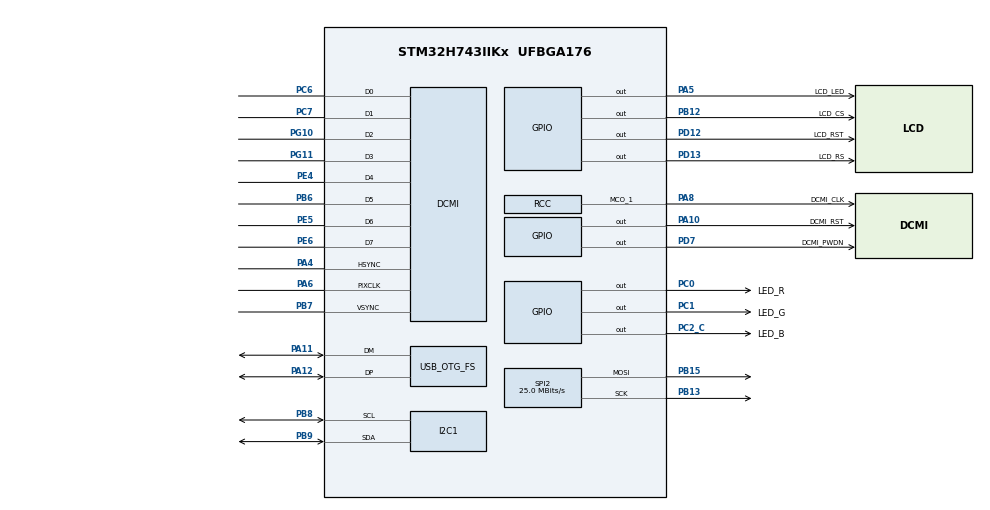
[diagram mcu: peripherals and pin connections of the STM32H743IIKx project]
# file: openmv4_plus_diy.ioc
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CORTEX_M7.CPU_DCache=Disabled
CORTEX_M7.CPU_ICache=Enabled
CORTEX_M7.MPU_Control=__NULL
CORTEX_M7.default_mode_Activation=1
DCMI.HSPolarity=DCMI_HSPOLARITY_LOW
DCMI.JPEGMode=DCMI_JPEG_ENABLE
DCMI.PCKPolarity=DCMI_PCKPOLARITY_RISING
DCMI.VSPolarity=DCMI_VSPOLARITY_LOW
Dma.DCMI.0.Direction=DMA_PERIPH_TO_MEMORY
Dma.DCMI.0.EventEnable=DISABLE
Dma.DCMI.0.FIFOMode=DMA_FIFOMODE_ENABLE
Dma.DCMI.0.FIFOThreshold=DMA_FIFO_THRESHOLD_HALFFULL
Dma.DCMI.0.Instance=DMA1_Stream1
Dma.DCMI.0.MemBurst=DMA_MBURST_SINGLE
Dma.DCMI.0.MemDataAlignment=DMA_MDATAALIGN_WORD
Dma.DCMI.0.MemInc=DMA_MINC_ENABLE
Dma.DCMI.0.Mode=DMA_CIRCULAR
Dma.DCMI.0.PeriphBurst=DMA_PBURST_SINGLE
Dma.DCMI.0.PeriphDataAlignment=DMA_PDATAALIGN_WORD
Dma.DCMI.0.PeriphInc=DMA_PINC_DISABLE
Dma.DCMI.0.Polarity=HAL_DMAMUX_REQ_GEN_RISING
Dma.DCMI.0.Priority=DMA_PRIORITY_HIGH
Dma.DCMI.0.RequestNumber=1
Dma.DCMI.0.SignalID=NONE
Dma.DCMI.0.SyncEnable=DISABLE
Dma.DCMI.0.SyncPolarity=HAL_DMAMUX_SYNC_NO_EVENT
Dma.DCMI.0.SyncRequestNumber=1
Dma.DCMI.0.SyncSignalID=NONE
Dma.Request0=DCMI
Dma.Request1=SPI2_TX
Dma.SPI2_TX.1.Direction=DMA_MEMORY_TO_PERIPH
Dma.SPI2_TX.1.EventEnable=DISABLE
Dma.SPI2_TX.1.FIFOMode=DMA_FIFOMODE_DISABLE
Dma.SPI2_TX.1.Instance=DMA1_Stream5
Dma.SPI2_TX.1.MemDataAlignment=DMA_MDATAALIGN_HALFWORD
Dma.SPI2_TX.1.MemInc=DMA_MINC_ENABLE
Dma.SPI2_TX.1.Mode=DMA_NORMAL
Dma.SPI2_TX.1.PeriphDataAlignment=DMA_PDATAALIGN_HALFWORD
Dma.SPI2_TX.1.PeriphInc=DMA_PINC_DISABLE
Dma.SPI2_TX.1.Polarity=HAL_DMAMUX_REQ_GEN_RISING
Dma.SPI2_TX.1.Priority=DMA_PRIORITY_LOW
Dma.SPI2_TX.1.RequestNumber=1
Dma.SPI2_TX.1.SignalID=NONE
Dma.SPI2_TX.1.SyncEnable=DISABLE
Dma.SPI2_TX.1.SyncPolarity=HAL_DMAMUX_SYNC_NO_EVENT
Dma.SPI2_TX.1.SyncRequestNumber=1
Dma.SPI2_TX.1.SyncSignalID=NONE
I2C1.Timing=0x10C0ECFF
Mcu.Family=STM32H7
Mcu.Name=STM32H743IIKx
Mcu.Package=UFBGA176
NVIC.DCMI_IRQn=true\:0\:0\:false\:false\:true\:true\:true\:true
NVIC.DMA1_Stream1_IRQn=true\:0\:0\:false\:false\:true\:false\:true\:true
NVIC.DMA1_Stream5_IRQn=true\:3\:0\:true\:false\:true\:false\:true\:true
NVIC.OTG_FS_IRQn=true\:0\:0\:false\:false\:true\:false\:true\:true
NVIC.PriorityGroup=NVIC_PRIORITYGROUP_4
NVIC.SPI2_IRQn=true\:2\:0\:true\:false\:true\:false\:true\:true
PA10.GPIO_Label=DCMI_RST
PA10.GPIO_PuPd=GPIO_PULLUP
PA10.PinState=GPIO_PIN_SET
PA10.Signal=GPIO_Output
PA11.Mode=Device_Only
PA11.Signal=USB_OTG_FS_DM
PA12.Mode=Device_Only
PA12.Signal=USB_OTG_FS_DP
PA13\ (JTMS/SWDIO).Mode=Serial_Wire
PA13\ (JTMS/SWDIO).Signal=DEBUG_JTMS-SWDIO
PA14\ (JTCK/SWCLK).Mode=Serial_Wire
PA14\ (JTCK/SWCLK).Signal=DEBUG_JTCK-SWCLK
PA4.GPIO_Speed=GPIO_SPEED_FREQ_VERY_HIGH
PA4.Mode=Slave_8_bits_External_Synchro
PA4.Signal=DCMI_HSYNC
PA5.GPIO_Label=LCD_LED
PA5.Signal=GPIO_Output
PA6.GPIO_PuPd=GPIO_PULLUP
PA6.GPIO_Speed=GPIO_SPEED_FREQ_VERY_HIGH
PA6.Mode=Slave_8_bits_External_Synchro
PA6.Signal=DCMI_PIXCLK
PA8.GPIO_Label=DCMI_CLK
PA8.GPIO_Speed=GPIO_SPEED_FREQ_VERY_HIGH
PA8.Mode=Clock-out-1
PA8.Signal=RCC_MCO_1
PB12.GPIO_Label=LCD_CS
PB12.Signal=GPIO_Output
PB13.Mode=TX_Only_Simplex_Unidirect_Master
PB13.Signal=SPI2_SCK
PB14.Signal=SPI2_MISO
PB15.Mode=TX_Only_Simplex_Unidirect_Master
PB15.Signal=SPI2_MOSI
PB6.GPIO_Speed=GPIO_SPEED_FREQ_VERY_HIGH
PB6.Mode=Slave_8_bits_External_Synchro
PB6.Signal=DCMI_D5
PB7.GPIO_Speed=GPIO_SPEED_FREQ_VERY_HIGH
PB7.Mode=Slave_8_bits_External_Synchro
PB7.Signal=DCMI_VSYNC
PB8.Mode=I2C
PB8.Signal=I2C1_SCL
PB9.Mode=I2C
PB9.Signal=I2C1_SDA
PC0.GPIO_Label=LED_R
PC0.PinState=GPIO_PIN_SET
PC0.Signal=GPIO_Output
PC1.GPIO_Label=LED_G
PC1.PinState=GPIO_PIN_SET
PC1.Signal=GPIO_Output
PC2_C.GPIO_Label=LED_B
PC2_C.PinState=GPIO_PIN_SET
PC2_C.Signal=GPIO_Output
PC6.GPIO_Speed=GPIO_SPEED_FREQ_VERY_HIGH
PC6.Mode=Slave_8_bits_External_Synchro
PC6.Signal=DCMI_D0
PC7.GPIO_Speed=GPIO_SPEED_FREQ_VERY_HIGH
PC7.Mode=Slave_8_bits_External_Synchro
PC7.Signal=DCMI_D1
PD12.GPIO_Label=LCD_RST
PD12.Signal=GPIO_Output
PD13.GPIO_Label=LCD_RS
PD13.Signal=GPIO_Output
PD7.GPIO_Label=DCMI_PWDN
PD7.GPIO_PuPd=GPIO_PULLUP
PD7.PinState=GPIO_PIN_SET
PD7.Signal=GPIO_Output
PE4.GPIO_Speed=GPIO_SPEED_FREQ_VERY_HIGH
PE4.Mode=Slave_8_bits_External_Synchro
PE4.Signal=DCMI_D4
PE5.GPIO_Speed=GPIO_SPEED_FREQ_VERY_HIGH
PE5.Mode=Slave_8_bits_External_Synchro
PE5.Signal=DCMI_D6
PE6.GPIO_Speed=GPIO_SPEED_FREQ_VERY_HIGH
PE6.Mode=Slave_8_bits_External_Synchro
PE6.Signal=DCMI_D7
PG10.GPIO_Speed=GPIO_SPEED_FREQ_VERY_HIGH
PG10.Mode=Slave_8_bits_External_Synchro
PG10.Signal=DCMI_D2
PG11.GPIO_Speed=GPIO_SPEED_FREQ_VERY_HIGH
PG11.Mode=Slave_8_bits_External_Synchro
PG11.Signal=DCMI_D3
PH0-OSC_IN\ (PH0).Mode=HSE-External-Oscillator
PH0-OSC_IN\ (PH0).Signal=RCC_OSC_IN
PH1-OSC_OUT\ (PH1).Mode=HSE-External-Oscillator
PH1-OSC_OUT\ (PH1).Signal=RCC_OSC_OUT
ProjectManager.HeapSize=0x2000
ProjectManager.StackSize=0x4000
ProjectManager.TargetToolchain=STM32CubeIDE
RCC.ADCFreq_Value=24187500
RCC.APB1Freq_Value=100000000
RCC.APB2Freq_Value=100000000
RCC.APB3Freq_Value=100000000
RCC.APB4Freq_Value=100000000
RCC.CortexFreq_Value=400000000
RCC.D1PPRE=RCC_APB3_DIV2
RCC.D2PPRE1=RCC_APB1_DIV2
RCC.D2PPRE2=RCC_APB2_DIV2
RCC.D3PPRE=RCC_APB4_DIV2
RCC.DIVM1=3
RCC.DIVM3=20
RCC.DIVN1=200
RCC.DIVQ1=8
RCC.HCLKFreq_Value=200000000
RCC.HPRE=RCC_HCLK_DIV2
RCC.HSE_VALUE=12000000
RCC.PLL2FRACN=0
RCC.PLL3FRACN=0
RCC.PLLFRACN=0
RCC.PLLSourceVirtual=RCC_PLLSOURCE_HSE
RCC.RCC_MCO1Source=RCC_MCO1SOURCE_HSI48
RCC.SYSCLKFreq_VALUE=400000000
RCC.SYSCLKSource=RCC_SYSCLKSOURCE_PLLCLK
RCC.Tim1Mul=2
RCC.USBCLockSelection=RCC_USBCLKSOURCE_HSI48
RCC.USBFreq_Value=48000000
SPI2.BaudRatePrescaler=SPI_BAUDRATEPRESCALER_4
SPI2.CalculateBaudRate=25.0 MBits/s
SPI2.DataSize=SPI_DATASIZE_8BIT
SPI2.Direction=SPI_DIRECTION_2LINES_TXONLY
SPI2.Mode=SPI_MODE_MASTER
SPI2.VirtualType=VM_MASTER
USB_DEVICE.CLASS_NAME_FS=CDC
USB_DEVICE.VirtualMode-CDC_FS=Cdc
USB_DEVICE.VirtualModeFS=Cdc_FS
USB_OTG_FS.VirtualMode=Device_Only
VP_CRC_VS_CRC.Mode=CRC_Activate
VP_USB_DEVICE_VS_USB_DEVICE_CDC_FS.Mode=CDC_FS
board=custom

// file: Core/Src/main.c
/* USER CODE BEGIN Header */
/**
  ******************************************************************************
  * @file           : main.c
  * @brief          : Main program body
  ******************************************************************************
  * @attention
  *
  * Copyright (c) 2023 STMicroelectronics.
  * All rights reserved.
  *
  * This software is licensed under terms that can be found in the LICENSE file
  * in the root directory of this software component.
  * If no LICENSE file comes with this software, it is provided AS-IS.
  *
  ******************************************************************************
  */
/* USER CODE END Header */
#include "main.h"
#include "crc.h"
#include "dcmi.h"
#include "dma.h"
#include "i2c.h"
#include "spi.h"
#include "usb_device.h"
#include "gpio.h"

/* USER CODE BEGIN Includes */
#include "usb_bsp.h"
#include "camera_run.h"
#include "lcd_display.h"
/* USER CODE END Includes */

void SystemClock_Config(void);

/* USER CODE BEGIN 0 */
uint8_t test_buf[100];
/* USER CODE END 0 */

int main(void)
{

  /* Enable I-Cache---------------------------------------------------------*/
  SCB_EnableICache();

  /* MCU Configuration--------------------------------------------------------*/

  /* Reset of all peripherals, Initializes the Flash interface and the Systick. */
  HAL_Init();

  /* Configure the system clock */
  SystemClock_Config();

  /* Initialize all configured peripherals */
  MX_GPIO_Init();
  MX_DMA_Init();
  MX_USB_DEVICE_Init();
  MX_DCMI_Init();
  MX_I2C1_Init();
  MX_SPI2_Init();
  MX_CRC_Init();

  /* Infinite loop */
  /* USER CODE BEGIN WHILE */
  usb_printf("openmv4 plus board diy\r\n");
  lcd_init();
  camera_RGB565_init();
//  camera_JPEG_init();
  while (1)
  {
    /* USER CODE END WHILE */

    /* USER CODE BEGIN 3 */
//	  usb_send_data(test_buf,100);
//	  usb_printf("openmv4 plus board diy\r\n");
//	  HAL_Delay(1000);
//	  HAL_GPIO_TogglePin(LED_R_GPIO_Port,LED_R_Pin);
//	  HAL_GPIO_TogglePin(LED_G_GPIO_Port,LED_G_Pin);
//	  HAL_GPIO_TogglePin(LED_B_GPIO_Port,LED_B_Pin);
	  TFT_LCD_RGB565_run();
//	  JPEG_run();
  }
  /* USER CODE END 3 */
}

void SystemClock_Config(void)
{
  RCC_OscInitTypeDef RCC_OscInitStruct = {0};
  RCC_ClkInitTypeDef RCC_ClkInitStruct = {0};

  /** Supply configuration update enable
  */
  HAL_PWREx_ConfigSupply(PWR_LDO_SUPPLY);

  /** Configure the main internal regulator output voltage
  */
  __HAL_PWR_VOLTAGESCALING_CONFIG(PWR_REGULATOR_VOLTAGE_SCALE1);

  while(!__HAL_PWR_GET_FLAG(PWR_FLAG_VOSRDY)) {}

  /** Initializes the RCC Oscillators according to the specified parameters
  * in the RCC_OscInitTypeDef structure.
  */
  RCC_OscInitStruct.OscillatorType = RCC_OSCILLATORTYPE_HSI48|RCC_OSCILLATORTYPE_HSE;
  RCC_OscInitStruct.HSEState = RCC_HSE_ON;
  RCC_OscInitStruct.HSI48State = RCC_HSI48_ON;
  RCC_OscInitStruct.PLL.PLLState = RCC_PLL_ON;
  RCC_OscInitStruct.PLL.PLLSource = RCC_PLLSOURCE_HSE;
  RCC_OscInitStruct.PLL.PLLM = 3;
  RCC_OscInitStruct.PLL.PLLN = 200;
  RCC_OscInitStruct.PLL.PLLP = 2;
  RCC_OscInitStruct.PLL.PLLQ = 8;
  RCC_OscInitStruct.PLL.PLLR = 2;
  RCC_OscInitStruct.PLL.PLLRGE = RCC_PLL1VCIRANGE_2;
  RCC_OscInitStruct.PLL.PLLVCOSEL = RCC_PLL1VCOWIDE;
  RCC_OscInitStruct.PLL.PLLFRACN = 0;
  if (HAL_RCC_OscConfig(&RCC_OscInitStruct) != HAL_OK)
  {
    Error_Handler();
  }

  /** Initializes the CPU, AHB and APB buses clocks
  */
  RCC_ClkInitStruct.ClockType = RCC_CLOCKTYPE_HCLK|RCC_CLOCKTYPE_SYSCLK
                              |RCC_CLOCKTYPE_PCLK1|RCC_CLOCKTYPE_PCLK2
                              |RCC_CLOCKTYPE_D3PCLK1|RCC_CLOCKTYPE_D1PCLK1;
  RCC_ClkInitStruct.SYSCLKSource = RCC_SYSCLKSOURCE_PLLCLK;
  RCC_ClkInitStruct.SYSCLKDivider = RCC_SYSCLK_DIV1;
  RCC_ClkInitStruct.AHBCLKDivider = RCC_HCLK_DIV2;
  RCC_ClkInitStruct.APB3CLKDivider = RCC_APB3_DIV2;
  RCC_ClkInitStruct.APB1CLKDivider = RCC_APB1_DIV2;
  RCC_ClkInitStruct.APB2CLKDivider = RCC_APB2_DIV2;
  RCC_ClkInitStruct.APB4CLKDivider = RCC_APB4_DIV2;

  if (HAL_RCC_ClockConfig(&RCC_ClkInitStruct, FLASH_LATENCY_2) != HAL_OK)
  {
    Error_Handler();
  }
  HAL_RCC_MCOConfig(RCC_MCO1, RCC_MCO1SOURCE_HSI48, RCC_MCODIV_1);
}

void Error_Handler(void)
{
  __disable_irq();
  while (1)
  {
  }
}
